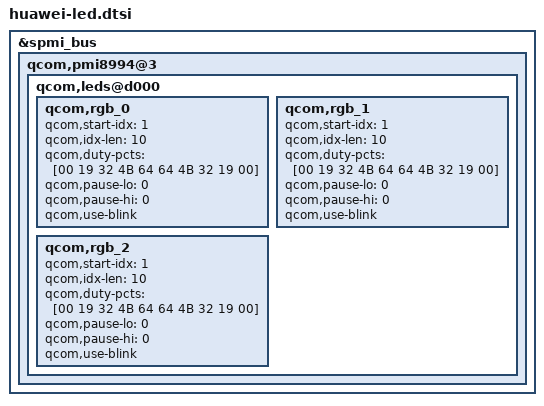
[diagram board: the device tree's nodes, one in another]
/* Copyright (c) 2014-2015, The Linux Foundation. All rights reserved.
 *
 * This program is free software; you can redistribute it and/or modify
 * it under the terms of the GNU General Public License version 2 and
 * only version 2 as published by the Free Software Foundation.
 *
 * This program is distributed in the hope that it will be useful,
 * but WITHOUT ANY WARRANTY; without even the implied warranty of
 * MERCHANTABILITY or FITNESS FOR A PARTICULAR PURPOSE.  See the
 * GNU General Public License for more details.
 */

&spmi_bus {
	qcom,pmi8994@3 {
		qcom,leds@d000 {
			qcom,rgb_0 {
				qcom,start-idx = <1>;
				qcom,idx-len = <10>;
				qcom,duty-pcts = [00 19 32 4B 64 64 4B 32 19 00];
				qcom,pause-lo = <0>;
				qcom,pause-hi = <0>;
				qcom,use-blink;
			};

			qcom,rgb_1 {
				qcom,start-idx = <1>;
				qcom,idx-len = <10>;
				qcom,duty-pcts = [00 19 32 4B 64 64 4B 32 19 00];
				qcom,pause-lo = <0>;
				qcom,pause-hi = <0>;
				qcom,use-blink;
			};

			qcom,rgb_2 {
				qcom,start-idx = <1>;
				qcom,idx-len = <10>;
				qcom,duty-pcts = [00 19 32 4B 64 64 4B 32 19 00];
				qcom,pause-lo = <0>;
				qcom,pause-hi = <0>;
				qcom,use-blink;
			};
		};
	};
};
